# UPD70F3508 register map
Vendor: Renesas; Series: V850E2/Px4; File version: 1.0
CPU: other r0p0, little endian, no MPU, FPU, 4 interrupt priority bits
Registers are 8-bit, read-write, reset 0x0 unless marked. A register's access mark holds for its fields unless they carry their own. Offsets are from the block's base; [hi:lo] are bit positions; lines under a group give offsets from that group; {n}, {i} and the like mark numbered series.

## PIC — Peripheral Interconnection Controller 0 — main register cluster (merged: PIC0, PIC0_TAPA)
Base 0xFF81C080
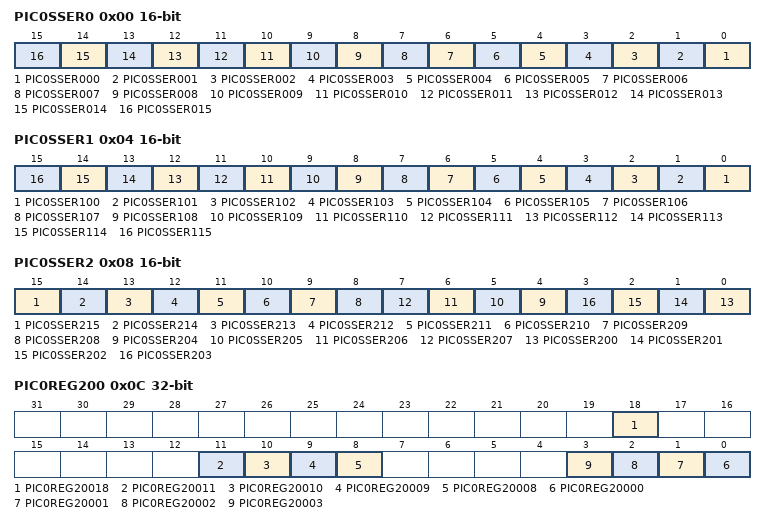
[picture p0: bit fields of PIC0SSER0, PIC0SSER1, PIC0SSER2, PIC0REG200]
0x00 PIC0SSER0 16-bit — Simultaneous start control register 0 — enables simultaneous start trigger for TAUA0 channels
  [n] PIC0SSER{n:03} (n=0..15) — Enable simultaneous start trigger for TAUA0 CH{n:02}
0x04 PIC0SSER1 16-bit — Simultaneous start control register 1 — enables simultaneous start trigger for TAUA1 channels
  [n-100] PIC0SSER{n} (n=100..115) — Enable simultaneous start trigger for TAUA1 CH{n-100:02}
0x08 PIC0SSER2 16-bit — Simultaneous start control register 2 — enables simultaneous start trigger for TAUJ/TSG2/TPBA/OSTM/ENCA
  [15] PIC0SSER215 — Enable simultaneous start trigger for ENCA1
  [14] PIC0SSER214 — Enable simultaneous start trigger for ENCA0
  [13] PIC0SSER213 — Enable simultaneous start trigger for OSTM1
  [12] PIC0SSER212 — Enable simultaneous start trigger for OSTM0
  [11] PIC0SSER211 — Enable simultaneous start trigger for TPBA1
  [10] PIC0SSER210 — Enable simultaneous start trigger for TPBA0
  [9] PIC0SSER209 — Enable simultaneous start trigger for TSG21
  [8] PIC0SSER208 — Enable simultaneous start trigger for TSG20
  [n-200] PIC0SSER{n} (n=204..207) — Enable simultaneous start trigger for TAUJ1 CH{n-204:02}
  [n-200] PIC0SSER{n} (n=200..203) — Enable simultaneous start trigger for TAUJ0 CH{n-200:02}
0x0C PIC0REG200 32-bit — Timer I/O control register 200 (PIC0REG2n0, n=0) — selects TIN input signal for TAUA0; used by high-accuracy triangle-wave PWM and three-phase pulse input functions
  [18] PIC0REG20018 — Select TIN input of TAUA0 CH10/CH12/CH14 — selects TOUT of TAUA0 CH02 when set
  [11] PIC0REG20011 — TS0PET signal select (high bits) for three-phase pulse input (TAUA0)
  [10] PIC0REG20010 — TS0PET signal select (low bits) for three-phase pulse input (TAUA0)
  [9] PIC0REG20009 — TS0PET signal select (high bits) for three-phase pulse input (TAUA0)
  [8] PIC0REG20008 — TS0PET signal select (low bits) for three-phase pulse input (TAUA0)
  [n-20000] PIC0REG{n} (n=20000..20003) — Select TAUA0 TAI{n-19996:03} pin or TS0PTE signal of TSG20
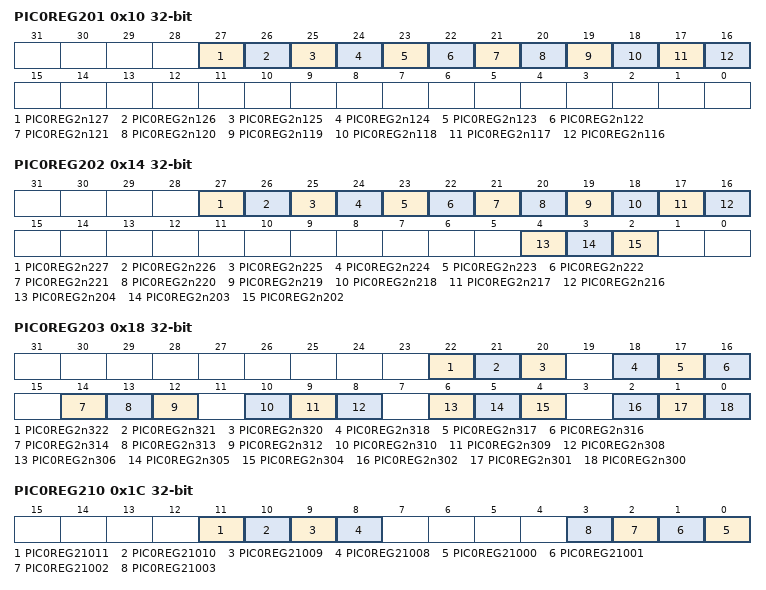
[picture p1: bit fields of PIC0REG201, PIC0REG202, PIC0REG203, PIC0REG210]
0x10 PIC0REG201 32-bit — Timer I/O control register 201 (PIC0REG2n1, n=0) — selects TIN input signal for TAUA0 one-phase PWM; combinational circuit input select
  [27] PIC0REG2n127 — Select A input of FN05 per TOL of TAUA0 CH09 (bit 27)
  [26] PIC0REG2n126 — Select A input of FN05 per TOL of TAUA0 CH09 (bit 26)
  [25] PIC0REG2n125 — Select A input of FN04 per TOL of TAUA0 CH08 (bit 25)
  [24] PIC0REG2n124 — Select A input of FN04 per TOL of TAUA0 CH08 (bit 24)
  [23] PIC0REG2n123 — Select A input of FN03 per TOL of TAUA0 CH07 (bit 23)
  [22] PIC0REG2n122 — Select A input of FN03 per TOL of TAUA0 CH07 (bit 22)
  [21] PIC0REG2n121 — Select A input of FN02 per TOL of TAUA0 CH06 (bit 21)
  [20] PIC0REG2n120 — Select A input of FN02 per TOL of TAUA0 CH06 (bit 20)
  [19] PIC0REG2n119 — Select A input of FN01 per TOL of TAUA0 CH05 (bit 19)
  [18] PIC0REG2n118 — Select A input of FN01 per TOL of TAUA0 CH05 (bit 18)
  [17] PIC0REG2n117 — Select A input of FN00 per TOL of TAUA0 CH04 (bit 17)
  [16] PIC0REG2n116 — Select A input of FN00 per TOL of TAUA0 CH04 (bit 16)
0x14 PIC0REG202 32-bit — Timer I/O control register 202 (PIC0REG2n2, n=0) — selects TIN input signal for TAUA0 one-phase PWM output / three-phase PWM output functions
  [27] PIC0REG2n227 — Select TIN input of TAUA0 CH15 (bit 27 — upper of pair)
  [26] PIC0REG2n226 — Select TIN input of TAUA0 CH15 (bit 26 — lower of pair)
  [25] PIC0REG2n225 — Select TIN input of TAUA0 CH14 (bit 25 — upper of pair; high-accuracy triangle-wave)
  [24] PIC0REG2n224 — Select TIN input of TAUA0 CH14 (bit 24 — lower of pair; high-accuracy triangle-wave)
  [23] PIC0REG2n223 — Select TIN input of TAUA0 CH13 (bit 23 — upper of pair)
  [22] PIC0REG2n222 — Select TIN input of TAUA0 CH13 (bit 22 — lower of pair)
  [21] PIC0REG2n221 — Select TIN input of TAUA0 CH12 (bit 21 — upper of pair; high-accuracy triangle-wave)
  [20] PIC0REG2n220 — Select TIN input of TAUA0 CH12 (bit 20 — lower of pair; high-accuracy triangle-wave)
  [19] PIC0REG2n219 — Select TIN input of TAUA0 CH11 (bit 19 — upper of pair)
  [18] PIC0REG2n218 — Select TIN input of TAUA0 CH11 (bit 18 — lower of pair)
  [17] PIC0REG2n217 — Select TIN input of TAUA0 CH10 (bit 17 — upper of pair; high-accuracy triangle-wave)
  [16] PIC0REG2n216 — Select TIN input of TAUA0 CH10 (bit 16 — lower of pair; high-accuracy triangle-wave)
  [4] PIC0REG2n204 — Select TIN signal for TAUA0 CH15 (0=TOUT from CH09)
  [3] PIC0REG2n203 — Select TIN signal for TAUA0 CH13 (0=TOUT from CH07)
  [2] PIC0REG2n202 — Select TIN signal for TAUA0 CH11 (0=TOUT from CH05)
0x18 PIC0REG203 32-bit — Timer I/O control register 203 (PIC0REG2n3, n=0) — logical operation circuit select for TAUA0 high-accuracy triangle-wave PWM with dead time
  [22] PIC0REG2n322 — Logical operation select for TAUA0 CH09 (bit 22)
  [21] PIC0REG2n321 — Logical operation select for TAUA0 CH09 (bit 21)
  [20] PIC0REG2n320 — Logical operation select for TAUA0 CH09 (bit 20)
  [18] PIC0REG2n318 — Logical operation select for TAUA0 CH08 (bit 18)
  [17] PIC0REG2n317 — Logical operation select for TAUA0 CH08 (bit 17)
  [16] PIC0REG2n316 — Logical operation select for TAUA0 CH08 (bit 16)
  [14] PIC0REG2n314 — Logical operation select for TAUA0 CH07 (bit 14)
  [13] PIC0REG2n313 — Logical operation select for TAUA0 CH07 (bit 13)
  [12] PIC0REG2n312 — Logical operation select for TAUA0 CH07 (bit 12)
  [10] PIC0REG2n310 — Logical operation select for TAUA0 CH06 (bit 10)
  [9] PIC0REG2n309 — Logical operation select for TAUA0 CH06 (bit 9)
  [8] PIC0REG2n308 — Logical operation select for TAUA0 CH06 (bit 8)
  [6] PIC0REG2n306 — Logical operation select for TAUA0 CH05 (bit 6)
  [5] PIC0REG2n305 — Logical operation select for TAUA0 CH05 (bit 5)
  [4] PIC0REG2n304 — Logical operation select for TAUA0 CH05 (bit 4)
  [2] PIC0REG2n302 — Logical operation select for TAUA0 CH04 (bit 2)
  [1] PIC0REG2n301 — Logical operation select for TAUA0 CH04 (bit 1)
  [0] PIC0REG2n300 — Logical operation select for TAUA0 CH04 (bit 0)
0x1C PIC0REG210 32-bit — Timer I/O control register 210 (PIC0REG2n0, n=1) — selects TIN input signal for TAUA1; used by high-accuracy triangle-wave PWM and three-phase pulse input functions
  [11] PIC0REG21011 — TS1PET signal select (high bits) for three-phase pulse input (TAUA1)
  [10] PIC0REG21010 — TS1PET signal select (low bits) for three-phase pulse input (TAUA1)
  [9] PIC0REG21009 — TS1PET signal select (high bits) for three-phase pulse input (TAUA1)
  [8] PIC0REG21008 — TS1PET signal select (low bits) for three-phase pulse input (TAUA1)
  [n-21000] PIC0REG{n} (n=21000..21003) — Select TAUA1 TAI{n-20896} pin or TS1PTE signal of TSG21
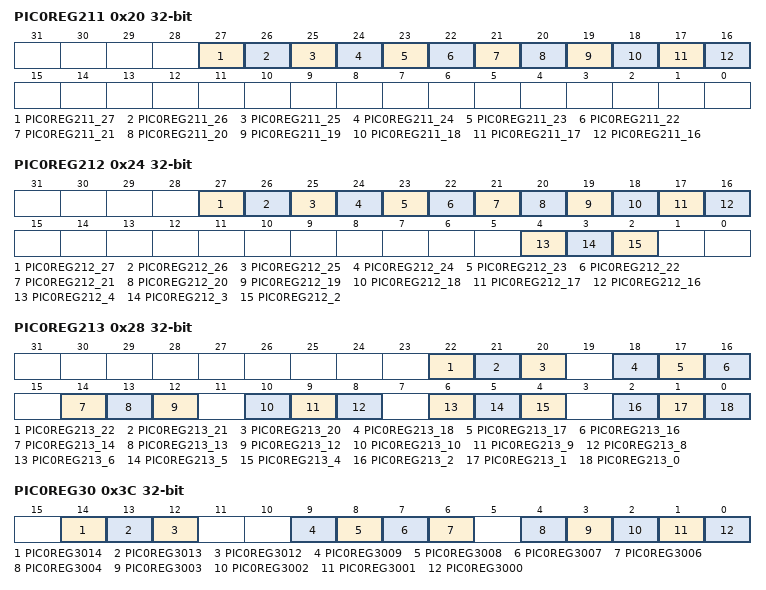
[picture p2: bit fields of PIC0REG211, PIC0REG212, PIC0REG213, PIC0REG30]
0x20 PIC0REG211 32-bit — Timer I/O control register 211 (PIC0REG2n1, n=1) — selects TIN input signal for TAUA1 one-phase PWM; combinational circuit input select
  [27] PIC0REG211_27 — Select A input of FN05 per TOL of TAUA1 CH09 (bit 27)
  [26] PIC0REG211_26 — Select A input of FN05 per TOL of TAUA1 CH09 (bit 26)
  [25] PIC0REG211_25 — Select A input of FN04 per TOL of TAUA1 CH08 (bit 25)
  [24] PIC0REG211_24 — Select A input of FN04 per TOL of TAUA1 CH08 (bit 24)
  [23] PIC0REG211_23 — Select A input of FN03 per TOL of TAUA1 CH07 (bit 23)
  [22] PIC0REG211_22 — Select A input of FN03 per TOL of TAUA1 CH07 (bit 22)
  [21] PIC0REG211_21 — Select A input of FN02 per TOL of TAUA1 CH06 (bit 21)
  [20] PIC0REG211_20 — Select A input of FN02 per TOL of TAUA1 CH06 (bit 20)
  [19] PIC0REG211_19 — Select A input of FN01 per TOL of TAUA1 CH05 (bit 19)
  [18] PIC0REG211_18 — Select A input of FN01 per TOL of TAUA1 CH05 (bit 18)
  [17] PIC0REG211_17 — Select A input of FN00 per TOL of TAUA1 CH04 (bit 17)
  [16] PIC0REG211_16 — Select A input of FN00 per TOL of TAUA1 CH04 (bit 16)
0x24 PIC0REG212 32-bit — Timer I/O control register 212 (PIC0REG2n2, n=1) — selects TIN input signal for TAUA1 one-phase PWM / three-phase PWM output functions
  [27] PIC0REG212_27 — Select TIN input of TAUA1 CH15 (bit 27)
  [26] PIC0REG212_26 — Select TIN input of TAUA1 CH15 (bit 26)
  [25] PIC0REG212_25 — Select TIN input of TAUA1 CH14 (bit 25)
  [24] PIC0REG212_24 — Select TIN input of TAUA1 CH14 (bit 24)
  [23] PIC0REG212_23 — Select TIN input of TAUA1 CH13 (bit 23)
  [22] PIC0REG212_22 — Select TIN input of TAUA1 CH13 (bit 22)
  [21] PIC0REG212_21 — Select TIN input of TAUA1 CH12 (bit 21)
  [20] PIC0REG212_20 — Select TIN input of TAUA1 CH12 (bit 20)
  [19] PIC0REG212_19 — Select TIN input of TAUA1 CH11 (bit 19)
  [18] PIC0REG212_18 — Select TIN input of TAUA1 CH11 (bit 18)
  [17] PIC0REG212_17 — Select TIN input of TAUA1 CH10 (bit 17)
  [16] PIC0REG212_16 — Select TIN input of TAUA1 CH10 (bit 16)
  [4] PIC0REG212_4 — Select TIN signal for TAUA1 CH15 (0=TOUT from CH09)
  [3] PIC0REG212_3 — Select TIN signal for TAUA1 CH13 (0=TOUT from CH07)
  [2] PIC0REG212_2 — Select TIN signal for TAUA1 CH11 (0=TOUT from CH05)
0x28 PIC0REG213 32-bit — Timer I/O control register 213 (PIC0REG2n3, n=1) — logical operation circuit select for TAUA1 high-accuracy triangle-wave PWM with dead time
  [22] PIC0REG213_22 — Logical operation select for TAUA1 CH09 (bit 22)
  [21] PIC0REG213_21 — Logical operation select for TAUA1 CH09 (bit 21)
  [20] PIC0REG213_20 — Logical operation select for TAUA1 CH09 (bit 20)
  [18] PIC0REG213_18 — Logical operation select for TAUA1 CH08 (bit 18)
  [17] PIC0REG213_17 — Logical operation select for TAUA1 CH08 (bit 17)
  [16] PIC0REG213_16 — Logical operation select for TAUA1 CH08 (bit 16)
  [14] PIC0REG213_14 — Logical operation select for TAUA1 CH07 (bit 14)
  [13] PIC0REG213_13 — Logical operation select for TAUA1 CH07 (bit 13)
  [12] PIC0REG213_12 — Logical operation select for TAUA1 CH07 (bit 12)
  [10] PIC0REG213_10 — Logical operation select for TAUA1 CH06 (bit 10)
  [9] PIC0REG213_9 — Logical operation select for TAUA1 CH06 (bit 9)
  [8] PIC0REG213_8 — Logical operation select for TAUA1 CH06 (bit 8)
  [6] PIC0REG213_6 — Logical operation select for TAUA1 CH05 (bit 6)
  [5] PIC0REG213_5 — Logical operation select for TAUA1 CH05 (bit 5)
  [4] PIC0REG213_4 — Logical operation select for TAUA1 CH05 (bit 4)
  [2] PIC0REG213_2 — Logical operation select for TAUA1 CH04 (bit 2)
  [1] PIC0REG213_1 — Logical operation select for TAUA1 CH04 (bit 1)
  [0] PIC0REG213_0 — Logical operation select for TAUA1 CH04 (bit 0)
0x34 PIC0HIZCEN0 — Hi-Z output control register 0 (address from Table 26-2 only; bit definitions not detailed in this section)
0x38 PIC0HIZCEN1 — Hi-Z output control register 1 (address from Table 26-2 only; bit definitions not detailed in this section)
0x3C PIC0REG30 32-bit — Timer I/O control register 30 — multi-function: A/D trigger encoder capture (bits 14:12, 4:2), two-phase encoder control (bits 9:8, 7:6, 1:0), three-phase encoder control
  [14] PIC0REG3014 — Select signal input to ENCAT1TIN1 (bit 14 — ADC trigger select high)
  [13] PIC0REG3013 — Select signal input to ENCAT1TIN1 (bit 13 — ADC trigger select mid)
  [12] PIC0REG3012 — Select signal input to ENCAT1TIN1 (bit 12 — ADC trigger select low)
  [9] PIC0REG3009 — Select ENCA1E1 pin input / TS1PUD signal of TSG21 (bit 9)
  [8] PIC0REG3008 — Select ENCA1E1 pin input / TS1PUD signal of TSG21 (bit 8)
  [7] PIC0REG3007 — Select ENCA1E0 pin input / TS1PEC signal of TSG21 (bit 7)
  [6] PIC0REG3006 — Select ENCA1E0 pin input / TS1PEC signal of TSG21 (bit 6)
  [4] PIC0REG3004 — Select signal input to ENCAT0TIN1 (bit 4 — ADC trigger select high)
  [3] PIC0REG3003 — Select signal input to ENCAT0TIN1 (bit 3 — ADC trigger select mid)
  [2] PIC0REG3002 — Select signal input to ENCAT0TIN1 (bit 2 — ADC trigger select low)
  [1] PIC0REG3001 — Select TS0PUD signal of TSG20 / ENCA0E1 pin input
  [0] PIC0REG3000 — Select TS0PEC signal of TSG20 / ENCA0E0 pin input
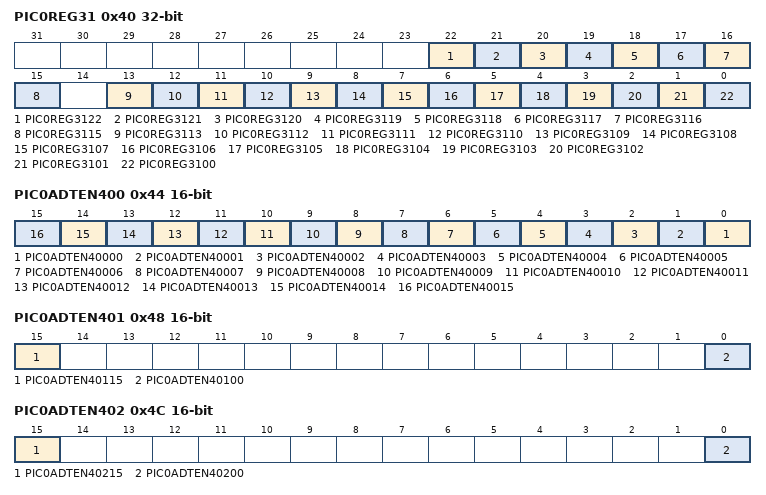
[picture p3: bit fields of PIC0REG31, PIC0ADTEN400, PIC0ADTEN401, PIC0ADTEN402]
0x40 PIC0REG31 32-bit — Timer I/O control register 31 — trigger and pulse width measurement (ENCA/TAUA/TAUJ signal routing) and CAN time stamp function
  [22] PIC0REG3122 — Select TIN signal input of TAUA1 CH02 (bit 22)
  [21] PIC0REG3121 — Select TIN signal input of TAUA1 CH02 (bit 21)
  [20] PIC0REG3120 — Select TIN signal input of TAUA1 CH01 (signal selected with bits 17:15)
  [19] PIC0REG3119 — Select TIN signal input of TAUA1 CH00 (bit 19)
  [18] PIC0REG3118 — Select TIN signal input of TAUA1 CH00 (bit 18)
  [17] PIC0REG3117 — Select TIN signal input of TAUA1 CH00 and CH01 (bit 17)
  [16] PIC0REG3116 — Select TIN signal input of TAUA1 CH00 and CH01 (bit 16)
  [15] PIC0REG3115 — Select TIN signal input of TAUA1 CH00 and CH01 (bit 15)
  [13] PIC0REG3113 — Select TIN signal input of TAUA0 CH02 (bit 13)
  [12] PIC0REG3112 — Select TIN signal input of TAUA0 CH02 (bit 12)
  [11] PIC0REG3111 — Select TIN signal input of TAUA0 CH01 (signal selected with bits 8:6)
  [10] PIC0REG3110 — Select TIN signal input of TAUA0 CH00 (bit 10)
  [9] PIC0REG3109 — Select TIN signal input of TAUA0 CH00 (bit 9)
  [8] PIC0REG3108 — Select TIN signal input of TAUA0 CH00 and CH01 (bit 8)
  [7] PIC0REG3107 — Select TIN signal input of TAUA0 CH00 and CH01 (bit 7)
  [6] PIC0REG3106 — Select TIN signal input of TAUA0 CH00 and CH01 (bit 6)
  [5] PIC0REG3105 — Select input of TAUJ0 CH3 — CAN1 time stamp (bit 5)
  [4] PIC0REG3104 — Select TIN of TAUJ0 CH03 / CAN1 TSOUT (bit 4)
  [3] PIC0REG3103 — Select TIN of TAUJ0 CH02 (DT output from ENCAT1IEC)
  [2] PIC0REG3102 — Select input of TAUJ0 CH1 — CAN0 time stamp (bit 2)
  [1] PIC0REG3101 — Select TIN of TAUJ0 CH01 / CAN0 TSOUT (bit 1)
  [0] PIC0REG3100 — Select TIN of TAUJ0 CH00 (DT output from ENCAT0IEC)
0x44 PIC0ADTEN400 16-bit — A/D converter trigger output control register 400 — enables TAUA0 channel interrupt trigger signals as ADC trigger for channel group 0
  [n-40000] PIC0ADTEN{n} (n=40000..40015) — Enable TAUA0 CH{n-40000:02} trigger as ADC trigger
0x48 PIC0ADTEN401 16-bit — A/D converter trigger output control register 401 — enables TAUA0 channel interrupt trigger signals as ADC trigger for channel group 1
  [15] PIC0ADTEN40115 — Enable TAUA0 CH15 trigger as ADC group 1 trigger
  [0] PIC0ADTEN40100 — Enable TAUA0 CH00 trigger as ADC group 1 trigger
0x4C PIC0ADTEN402 16-bit — A/D converter trigger output control register 402 — enables TAUA0 channel interrupt trigger signals as ADC trigger for channel group 2
  [15] PIC0ADTEN40215 — Enable TAUA0 CH15 trigger as ADC group 2 trigger
  [0] PIC0ADTEN40200 — Enable TAUA0 CH00 trigger as ADC group 2 trigger
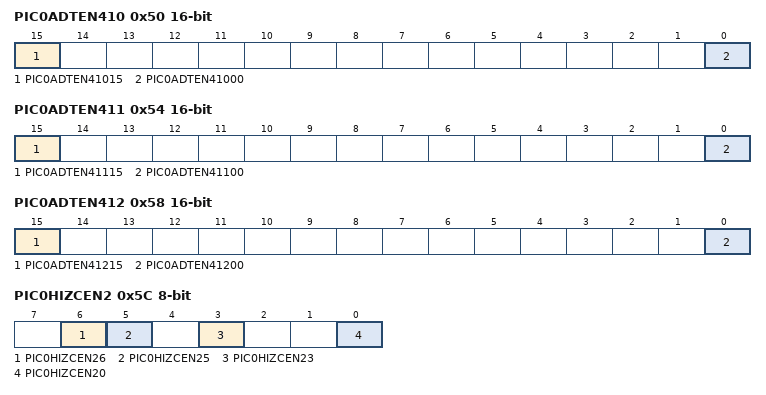
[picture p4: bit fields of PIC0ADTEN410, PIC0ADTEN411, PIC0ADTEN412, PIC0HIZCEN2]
0x50 PIC0ADTEN410 16-bit — A/D converter trigger output control register 410 — enables TAUA1 channel interrupt trigger signals as ADC trigger for channel group 0
  [15] PIC0ADTEN41015 — Enable TAUA1 CH15 trigger as ADC group 0 trigger
  [0] PIC0ADTEN41000 — Enable TAUA1 CH00 trigger as ADC group 0 trigger
0x54 PIC0ADTEN411 16-bit — A/D converter trigger output control register 411 — enables TAUA1 channel interrupt trigger signals as ADC trigger for channel group 1
  [15] PIC0ADTEN41115 — Enable TAUA1 CH15 trigger as ADC group 1 trigger
  [0] PIC0ADTEN41100 — Enable TAUA1 CH00 trigger as ADC group 1 trigger
0x58 PIC0ADTEN412 16-bit — A/D converter trigger output control register 412 — enables TAUA1 channel interrupt trigger signals as ADC trigger for channel group 2
  [15] PIC0ADTEN41215 — Enable TAUA1 CH15 trigger as ADC group 2 trigger
  [0] PIC0ADTEN41200 — Enable TAUA1 CH00 trigger as ADC group 2 trigger
0x5C PIC0HIZCEN2 — Hi-Z output control register 2 — controls Hi-Z output for TSG20/TAPA2 with INTADCA0TERR, ERROROUT, INTTSG20IER, ESO2 signals
  [6] PIC0HIZCEN26 — Enable Hi-Z output control with INTADCA0TERR interrupt signal
  [5] PIC0HIZCEN25 — Enable Hi-Z output control with ERROROUT signal
  [3] PIC0HIZCEN23 — Enable Hi-Z output control with INTTSG20IER interrupt signal
  [0] PIC0HIZCEN20 — Enable Hi-Z output control with ESO2 pin input
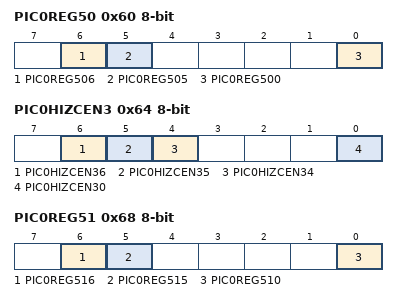
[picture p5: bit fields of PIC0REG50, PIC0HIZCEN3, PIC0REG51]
0x60 PIC0REG50 — Timer I/O control register 50 — selects timer input signal for two-phase encoder (ENCA0/TSG20) and three-phase pulse input / encoder functions
  [6] PIC0REG506 — Select TS0OPCI0 input: ENCA0TEQ1 or ENCA1TEQ1 / TAUA0CDEN5 (bit 6 — function-dependent)
  [5] PIC0REG505 — Select TS0OPCI0 input: ENCA0TEQ1 or ENCA1TEQ1 / TAUA0CDEN5 (bit 5 — function-dependent)
  [0] PIC0REG500 — Select TSG20PTSI0..2 pin inputs (three-phase encoder / three-phase pulse input)
0x64 PIC0HIZCEN3 — Hi-Z output control register 3 — controls Hi-Z output for TSG21/TAPA3 with INTADCA0TERR, ERROROUT, INTTSG21IER, ESO3 signals
  [6] PIC0HIZCEN36 — Enable Hi-Z output control with INTADCA0TERR interrupt signal
  [5] PIC0HIZCEN35 — Enable Hi-Z output control with ERROROUT signal
  [4] PIC0HIZCEN34 — Enable Hi-Z output control with INTTSG21IER interrupt signal
  [0] PIC0HIZCEN30 — Enable Hi-Z output control with ESO3 pin input
0x68 PIC0REG51 — Timer I/O control register 51 — selects timer input signal for two-phase encoder (ENCA1/TSG21) and three-phase pulse input / encoder functions
  [6] PIC0REG516 — Select TS1OPCI0 input: ENCA0TEQ1 or ENCA1TEQ1 / TAUA1CDEN5 (bit 6 — function-dependent)
  [5] PIC0REG515 — Select TS1OPCI0 input: ENCA0TEQ1 or ENCA1TEQ1 / TAUA1CDEN5 (bit 5 — function-dependent)
  [0] PIC0REG510 — Select TSG21PTSI0..2 pin inputs (three-phase encoder / three-phase pulse input)
